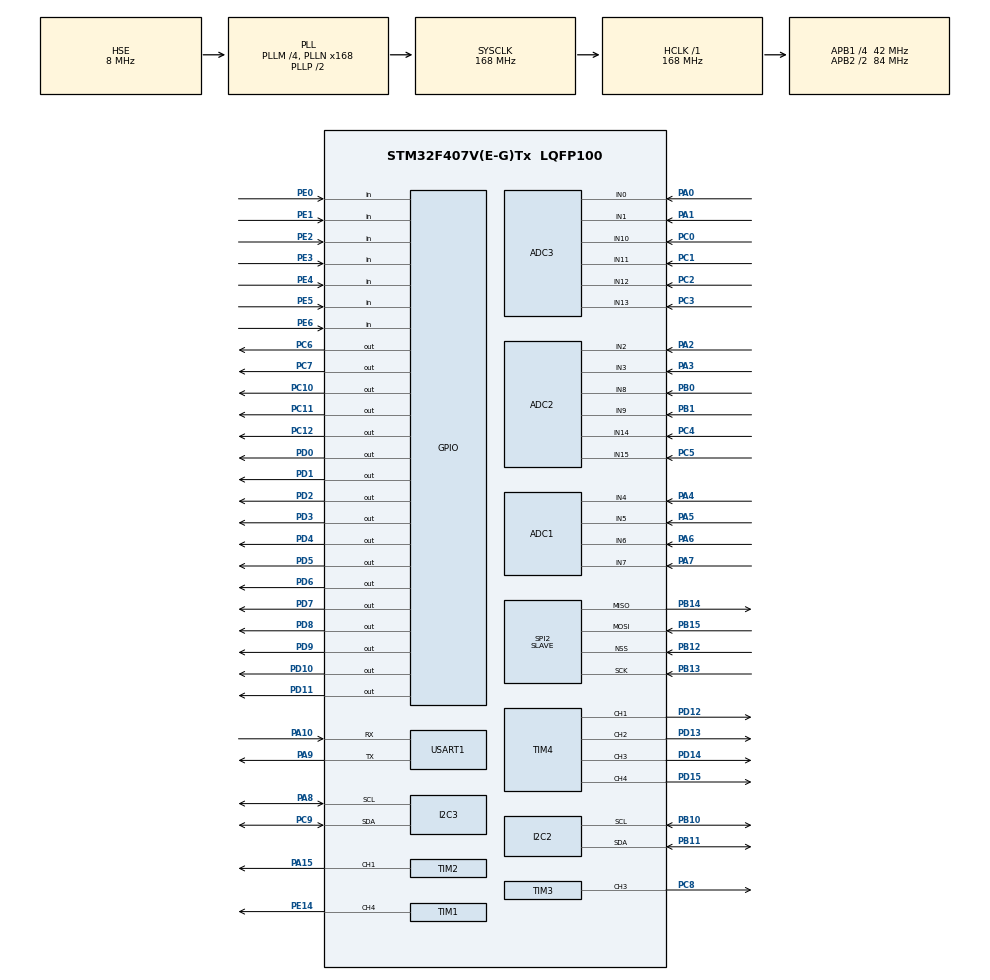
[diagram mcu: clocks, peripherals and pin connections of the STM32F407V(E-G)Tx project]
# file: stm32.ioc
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ADC1.Channel-0\#ChannelRegularConversion=ADC_CHANNEL_TEMPSENSOR
ADC1.ClockPrescaler=ADC_CLOCK_SYNC_PCLK_DIV4
ADC1.NbrOfConversionFlag=1
ADC1.Rank-0\#ChannelRegularConversion=1
ADC1.SamplingTime-0\#ChannelRegularConversion=ADC_SAMPLETIME_3CYCLES
ADC1.master=1
ADC2.Channel-3\#ChannelRegularConversion=ADC_CHANNEL_2
ADC2.ClockPrescaler=ADC_CLOCK_SYNC_PCLK_DIV4
ADC2.NbrOfConversionFlag=1
ADC2.Rank-3\#ChannelRegularConversion=1
ADC2.SamplingTime-3\#ChannelRegularConversion=ADC_SAMPLETIME_3CYCLES
ADC3.Channel-3\#ChannelRegularConversion=ADC_CHANNEL_10
ADC3.ClockPrescaler=ADC_CLOCK_SYNC_PCLK_DIV4
ADC3.NbrOfConversionFlag=1
ADC3.Rank-3\#ChannelRegularConversion=1
ADC3.SamplingTime-3\#ChannelRegularConversion=ADC_SAMPLETIME_3CYCLES
Mcu.Family=STM32F4
Mcu.Name=STM32F407V(E-G)Tx
Mcu.Package=LQFP100
NVIC.PriorityGroup=NVIC_PRIORITYGROUP_4
PA0-WKUP.Signal=ADCx_IN0
PA1.Signal=ADCx_IN1
PA10.Mode=Asynchronous
PA10.Signal=USART1_RX
PA13.Mode=Serial_Wire
PA13.Signal=SYS_JTMS-SWDIO
PA14.Mode=Serial_Wire
PA14.Signal=SYS_JTCK-SWCLK
PA15.Signal=S_TIM2_CH1_ETR
PA2.Signal=ADCx_IN2
PA3.Signal=ADCx_IN3
PA4.Signal=ADCx_IN4
PA5.Signal=ADCx_IN5
PA6.Signal=ADCx_IN6
PA7.Signal=ADCx_IN7
PA8.Mode=I2C
PA8.Signal=I2C3_SCL
PA9.Mode=Asynchronous
PA9.Signal=USART1_TX
PB0.Signal=ADCx_IN8
PB1.Signal=ADCx_IN9
PB10.Mode=I2C
PB10.Signal=I2C2_SCL
PB11.Mode=I2C
PB11.Signal=I2C2_SDA
PB12.Mode=NSS_Signal_Hard_Input
PB12.Signal=SPI2_NSS
PB13.Mode=Full_Duplex_Slave
PB13.Signal=SPI2_SCK
PB14.Mode=Full_Duplex_Slave
PB14.Signal=SPI2_MISO
PB15.Mode=Full_Duplex_Slave
PB15.Signal=SPI2_MOSI
PC0.Signal=ADCx_IN10
PC1.Signal=ADCx_IN11
PC10.Signal=GPIO_Output
PC11.Signal=GPIO_Output
PC12.Signal=GPIO_Output
PC14-OSC32_IN.Mode=LSE-External-Oscillator
PC14-OSC32_IN.Signal=RCC_OSC32_IN
PC15-OSC32_OUT.Mode=LSE-External-Oscillator
PC15-OSC32_OUT.Signal=RCC_OSC32_OUT
PC2.Signal=ADCx_IN12
PC3.Signal=ADCx_IN13
PC4.Signal=ADCx_IN14
PC5.Signal=ADCx_IN15
PC6.Signal=GPIO_Output
PC7.Signal=GPIO_Output
PC8.Signal=S_TIM3_CH3
PC9.Mode=I2C
PC9.Signal=I2C3_SDA
PD0.Signal=GPIO_Output
PD1.Signal=GPIO_Output
PD10.Signal=GPIO_Output
PD11.Signal=GPIO_Output
PD12.Signal=S_TIM4_CH1
PD13.Signal=S_TIM4_CH2
PD14.Signal=S_TIM4_CH3
PD15.Signal=S_TIM4_CH4
PD2.Signal=GPIO_Output
PD3.Signal=GPIO_Output
PD4.Signal=GPIO_Output
PD5.Signal=GPIO_Output
PD6.Signal=GPIO_Output
PD7.Signal=GPIO_Output
PD8.Signal=GPIO_Output
PD9.Signal=GPIO_Output
PE0.Signal=GPIO_Input
PE1.Signal=GPIO_Input
PE14.Signal=S_TIM1_CH4
PE2.Signal=GPIO_Input
PE3.Signal=GPIO_Input
PE4.Signal=GPIO_Input
PE5.Signal=GPIO_Input
PE6.Signal=GPIO_Input
PH0-OSC_IN.Mode=HSE-External-Oscillator
PH0-OSC_IN.Signal=RCC_OSC_IN
PH1-OSC_OUT.Mode=HSE-External-Oscillator
PH1-OSC_OUT.Signal=RCC_OSC_OUT
ProjectManager.HeapSize=0x200
ProjectManager.StackSize=0x400
ProjectManager.TargetToolchain=Makefile
RCC.48MHZClocksFreq_Value=84000000
RCC.AHBFreq_Value=168000000
RCC.APB1CLKDivider=RCC_HCLK_DIV4
RCC.APB1Freq_Value=42000000
RCC.APB1TimFreq_Value=84000000
RCC.APB2CLKDivider=RCC_HCLK_DIV2
RCC.APB2Freq_Value=84000000
RCC.APB2TimFreq_Value=168000000
RCC.CortexFreq_Value=168000000
RCC.HCLKFreq_Value=168000000
RCC.HSE_VALUE=8000000
RCC.HSI_VALUE=16000000
RCC.PLLM=4
RCC.PLLN=168
RCC.PLLSourceVirtual=RCC_PLLSOURCE_HSE
RCC.SYSCLKFreq_VALUE=168000000
RCC.SYSCLKSource=RCC_SYSCLKSOURCE_PLLCLK
RCC.VCOOutputFreq_Value=336000000
SH.ADCx_IN0.0=ADC3_IN0,IN0
SH.ADCx_IN1.0=ADC3_IN1,IN1
SH.ADCx_IN10.0=ADC3_IN10,IN10
SH.ADCx_IN11.0=ADC3_IN11,IN11
SH.ADCx_IN12.0=ADC3_IN12,IN12
SH.ADCx_IN13.0=ADC3_IN13,IN13
SH.ADCx_IN14.0=ADC2_IN14,IN14
SH.ADCx_IN15.0=ADC2_IN15,IN15
SH.ADCx_IN2.0=ADC2_IN2,IN2
SH.ADCx_IN3.0=ADC2_IN3,IN3
SH.ADCx_IN4.0=ADC1_IN4,IN4
SH.ADCx_IN5.0=ADC1_IN5,IN5
SH.ADCx_IN6.0=ADC1_IN6,IN6
SH.ADCx_IN7.0=ADC1_IN7,IN7
SH.ADCx_IN8.0=ADC2_IN8,IN8
SH.ADCx_IN9.0=ADC2_IN9,IN9
SH.S_TIM1_CH4.0=TIM1_CH4,PWM Generation4 CH4
SH.S_TIM2_CH1_ETR.0=TIM2_CH1,PWM Generation1 CH1
SH.S_TIM3_CH3.0=TIM3_CH3,PWM Generation3 CH3
SH.S_TIM4_CH1.0=TIM4_CH1,PWM Generation1 CH1
SH.S_TIM4_CH2.0=TIM4_CH2,PWM Generation2 CH2
SH.S_TIM4_CH3.0=TIM4_CH3,PWM Generation3 CH3
SH.S_TIM4_CH4.0=TIM4_CH4,PWM Generation4 CH4
SPI2.Direction=SPI_DIRECTION_2LINES
SPI2.Mode=SPI_MODE_SLAVE
SPI2.VirtualNSS=VM_NSSHARD
SPI2.VirtualType=VM_SLAVE
TIM1.Channel-PWM\ Generation4\ CH4=TIM_CHANNEL_4
TIM2.Channel-PWM\ Generation1\ CH1=TIM_CHANNEL_1
TIM2.Period=65535
TIM3.Channel-PWM\ Generation3\ CH3=TIM_CHANNEL_3
TIM4.Channel-PWM\ Generation1\ CH1=TIM_CHANNEL_1
TIM4.Channel-PWM\ Generation2\ CH2=TIM_CHANNEL_2
TIM4.Channel-PWM\ Generation3\ CH3=TIM_CHANNEL_3
TIM4.Channel-PWM\ Generation4\ CH4=TIM_CHANNEL_4
USART1.VirtualMode=VM_ASYNC
VP_ADC1_TempSens_Input.Mode=IN-TempSens
VP_ADC1_Vbat_Input.Mode=IN-Vbat
board=custom

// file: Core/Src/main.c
/* USER CODE BEGIN Header */
/**
  ******************************************************************************
  * @file           : main.c
  * @brief          : Main program body
  ******************************************************************************
  * @attention
  *
  * Copyright (c) 2024 STMicroelectronics.
  * All rights reserved.
  *
  * This software is licensed under terms that can be found in the LICENSE file
  * in the root directory of this software component.
  * If no LICENSE file comes with this software, it is provided AS-IS.
  *
  ******************************************************************************
  */
/* USER CODE END Header */
#include "main.h"

ADC_HandleTypeDef hadc1;
ADC_HandleTypeDef hadc2;
ADC_HandleTypeDef hadc3;

I2C_HandleTypeDef hi2c2;
I2C_HandleTypeDef hi2c3;

SPI_HandleTypeDef hspi2;

TIM_HandleTypeDef htim1;
TIM_HandleTypeDef htim2;
TIM_HandleTypeDef htim3;
TIM_HandleTypeDef htim4;

UART_HandleTypeDef huart1;

void SystemClock_Config(void);
static void MX_GPIO_Init(void);
static void MX_ADC1_Init(void);
static void MX_ADC2_Init(void);
static void MX_ADC3_Init(void);
static void MX_I2C2_Init(void);
static void MX_I2C3_Init(void);
static void MX_SPI2_Init(void);
static void MX_TIM1_Init(void);
static void MX_TIM2_Init(void);
static void MX_TIM3_Init(void);
static void MX_TIM4_Init(void);
static void MX_USART1_UART_Init(void);

/* USER CODE BEGIN 0 */

void foo() {
    __asm("nop");
}

void delay() {
    for (int i=0; i<1000000; ++i) {
        foo();
    }
}

/* USER CODE END 0 */

int main(void)
{

  /* MCU Configuration--------------------------------------------------------*/

  /* Reset of all peripherals, Initializes the Flash interface and the Systick. */
  HAL_Init();

  /* Configure the system clock */
  SystemClock_Config();

  /* Initialize all configured peripherals */
  MX_GPIO_Init();
  MX_ADC1_Init();
  MX_ADC2_Init();
  MX_ADC3_Init();
  MX_I2C2_Init();
  MX_I2C3_Init();
  MX_SPI2_Init();
  MX_TIM1_Init();
  MX_TIM2_Init();
  MX_TIM3_Init();
  MX_TIM4_Init();
  MX_USART1_UART_Init();

  /* Infinite loop */
  while (1)
  {
    HAL_GPIO_WritePin(GPIOC, GPIO_PIN_7, GPIO_PIN_RESET);
    delay();
    HAL_GPIO_WritePin(GPIOC, GPIO_PIN_7, GPIO_PIN_SET);
    delay();
  }
}

void SystemClock_Config(void)
{
  RCC_OscInitTypeDef RCC_OscInitStruct = {0};
  RCC_ClkInitTypeDef RCC_ClkInitStruct = {0};

  /** Configure the main internal regulator output voltage
  */
  __HAL_RCC_PWR_CLK_ENABLE();
  __HAL_PWR_VOLTAGESCALING_CONFIG(PWR_REGULATOR_VOLTAGE_SCALE1);

  /** Initializes the RCC Oscillators according to the specified parameters
  * in the RCC_OscInitTypeDef structure.
  */
  RCC_OscInitStruct.OscillatorType = RCC_OSCILLATORTYPE_HSE;
  RCC_OscInitStruct.HSEState = RCC_HSE_ON;
  RCC_OscInitStruct.PLL.PLLState = RCC_PLL_ON;
  RCC_OscInitStruct.PLL.PLLSource = RCC_PLLSOURCE_HSE;
  RCC_OscInitStruct.PLL.PLLM = 4;
  RCC_OscInitStruct.PLL.PLLN = 168;
  RCC_OscInitStruct.PLL.PLLP = RCC_PLLP_DIV2;
  RCC_OscInitStruct.PLL.PLLQ = 4;
  if (HAL_RCC_OscConfig(&RCC_OscInitStruct) != HAL_OK)
  {
    Error_Handler();
  }

  /** Initializes the CPU, AHB and APB buses clocks
  */
  RCC_ClkInitStruct.ClockType = RCC_CLOCKTYPE_HCLK|RCC_CLOCKTYPE_SYSCLK
                              |RCC_CLOCKTYPE_PCLK1|RCC_CLOCKTYPE_PCLK2;
  RCC_ClkInitStruct.SYSCLKSource = RCC_SYSCLKSOURCE_PLLCLK;
  RCC_ClkInitStruct.AHBCLKDivider = RCC_SYSCLK_DIV1;
  RCC_ClkInitStruct.APB1CLKDivider = RCC_HCLK_DIV4;
  RCC_ClkInitStruct.APB2CLKDivider = RCC_HCLK_DIV2;

  if (HAL_RCC_ClockConfig(&RCC_ClkInitStruct, FLASH_LATENCY_5) != HAL_OK)
  {
    Error_Handler();
  }
}

static void MX_ADC1_Init(void)
{

  ADC_ChannelConfTypeDef sConfig = {0};

  /** Configure the global features of the ADC (Clock, Resolution, Data Alignment and number of conversion)
  */
  hadc1.Instance = ADC1;
  hadc1.Init.ClockPrescaler = ADC_CLOCK_SYNC_PCLK_DIV4;
  hadc1.Init.Resolution = ADC_RESOLUTION_12B;
  hadc1.Init.ScanConvMode = DISABLE;
  hadc1.Init.ContinuousConvMode = DISABLE;
  hadc1.Init.DiscontinuousConvMode = DISABLE;
  hadc1.Init.ExternalTrigConvEdge = ADC_EXTERNALTRIGCONVEDGE_NONE;
  hadc1.Init.ExternalTrigConv = ADC_SOFTWARE_START;
  hadc1.Init.DataAlign = ADC_DATAALIGN_RIGHT;
  hadc1.Init.NbrOfConversion = 1;
  hadc1.Init.DMAContinuousRequests = DISABLE;
  hadc1.Init.EOCSelection = ADC_EOC_SINGLE_CONV;
  if (HAL_ADC_Init(&hadc1) != HAL_OK)
  {
    Error_Handler();
  }

  /** Configure for the selected ADC regular channel its corresponding rank in the sequencer and its sample time.
  */
  sConfig.Channel = ADC_CHANNEL_TEMPSENSOR;
  sConfig.Rank = 1;
  sConfig.SamplingTime = ADC_SAMPLETIME_3CYCLES;
  if (HAL_ADC_ConfigChannel(&hadc1, &sConfig) != HAL_OK)
  {
    Error_Handler();
  }

}

static void MX_ADC2_Init(void)
{

  ADC_ChannelConfTypeDef sConfig = {0};

  /** Configure the global features of the ADC (Clock, Resolution, Data Alignment and number of conversion)
  */
  hadc2.Instance = ADC2;
  hadc2.Init.ClockPrescaler = ADC_CLOCK_SYNC_PCLK_DIV4;
  hadc2.Init.Resolution = ADC_RESOLUTION_12B;
  hadc2.Init.ScanConvMode = DISABLE;
  hadc2.Init.ContinuousConvMode = DISABLE;
  hadc2.Init.DiscontinuousConvMode = DISABLE;
  hadc2.Init.ExternalTrigConvEdge = ADC_EXTERNALTRIGCONVEDGE_NONE;
  hadc2.Init.ExternalTrigConv = ADC_SOFTWARE_START;
  hadc2.Init.DataAlign = ADC_DATAALIGN_RIGHT;
  hadc2.Init.NbrOfConversion = 1;
  hadc2.Init.DMAContinuousRequests = DISABLE;
  hadc2.Init.EOCSelection = ADC_EOC_SINGLE_CONV;
  if (HAL_ADC_Init(&hadc2) != HAL_OK)
  {
    Error_Handler();
  }

  /** Configure for the selected ADC regular channel its corresponding rank in the sequencer and its sample time.
  */
  sConfig.Channel = ADC_CHANNEL_2;
  sConfig.Rank = 1;
  sConfig.SamplingTime = ADC_SAMPLETIME_3CYCLES;
  if (HAL_ADC_ConfigChannel(&hadc2, &sConfig) != HAL_OK)
  {
    Error_Handler();
  }

}

static void MX_ADC3_Init(void)
{

  ADC_ChannelConfTypeDef sConfig = {0};

  /** Configure the global features of the ADC (Clock, Resolution, Data Alignment and number of conversion)
  */
  hadc3.Instance = ADC3;
  hadc3.Init.ClockPrescaler = ADC_CLOCK_SYNC_PCLK_DIV4;
  hadc3.Init.Resolution = ADC_RESOLUTION_12B;
  hadc3.Init.ScanConvMode = DISABLE;
  hadc3.Init.ContinuousConvMode = DISABLE;
  hadc3.Init.DiscontinuousConvMode = DISABLE;
  hadc3.Init.ExternalTrigConvEdge = ADC_EXTERNALTRIGCONVEDGE_NONE;
  hadc3.Init.ExternalTrigConv = ADC_SOFTWARE_START;
  hadc3.Init.DataAlign = ADC_DATAALIGN_RIGHT;
  hadc3.Init.NbrOfConversion = 1;
  hadc3.Init.DMAContinuousRequests = DISABLE;
  hadc3.Init.EOCSelection = ADC_EOC_SINGLE_CONV;
  if (HAL_ADC_Init(&hadc3) != HAL_OK)
  {
    Error_Handler();
  }

  /** Configure for the selected ADC regular channel its corresponding rank in the sequencer and its sample time.
  */
  sConfig.Channel = ADC_CHANNEL_10;
  sConfig.Rank = 1;
  sConfig.SamplingTime = ADC_SAMPLETIME_3CYCLES;
  if (HAL_ADC_ConfigChannel(&hadc3, &sConfig) != HAL_OK)
  {
    Error_Handler();
  }

}

static void MX_I2C2_Init(void)
{

  hi2c2.Instance = I2C2;
  hi2c2.Init.ClockSpeed = 100000;
  hi2c2.Init.DutyCycle = I2C_DUTYCYCLE_2;
  hi2c2.Init.OwnAddress1 = 0;
  hi2c2.Init.AddressingMode = I2C_ADDRESSINGMODE_7BIT;
  hi2c2.Init.DualAddressMode = I2C_DUALADDRESS_DISABLE;
  hi2c2.Init.OwnAddress2 = 0;
  hi2c2.Init.GeneralCallMode = I2C_GENERALCALL_DISABLE;
  hi2c2.Init.NoStretchMode = I2C_NOSTRETCH_DISABLE;
  if (HAL_I2C_Init(&hi2c2) != HAL_OK)
  {
    Error_Handler();
  }

}

static void MX_I2C3_Init(void)
{

  hi2c3.Instance = I2C3;
  hi2c3.Init.ClockSpeed = 100000;
  hi2c3.Init.DutyCycle = I2C_DUTYCYCLE_2;
  hi2c3.Init.OwnAddress1 = 0;
  hi2c3.Init.AddressingMode = I2C_ADDRESSINGMODE_7BIT;
  hi2c3.Init.DualAddressMode = I2C_DUALADDRESS_DISABLE;
  hi2c3.Init.OwnAddress2 = 0;
  hi2c3.Init.GeneralCallMode = I2C_GENERALCALL_DISABLE;
  hi2c3.Init.NoStretchMode = I2C_NOSTRETCH_DISABLE;
  if (HAL_I2C_Init(&hi2c3) != HAL_OK)
  {
    Error_Handler();
  }

}

static void MX_SPI2_Init(void)
{

  /* SPI2 parameter configuration*/
  hspi2.Instance = SPI2;
  hspi2.Init.Mode = SPI_MODE_SLAVE;
  hspi2.Init.Direction = SPI_DIRECTION_2LINES;
  hspi2.Init.DataSize = SPI_DATASIZE_8BIT;
  hspi2.Init.CLKPolarity = SPI_POLARITY_LOW;
  hspi2.Init.CLKPhase = SPI_PHASE_1EDGE;
  hspi2.Init.NSS = SPI_NSS_HARD_INPUT;
  hspi2.Init.FirstBit = SPI_FIRSTBIT_MSB;
  hspi2.Init.TIMode = SPI_TIMODE_DISABLE;
  hspi2.Init.CRCCalculation = SPI_CRCCALCULATION_DISABLE;
  hspi2.Init.CRCPolynomial = 10;
  if (HAL_SPI_Init(&hspi2) != HAL_OK)
  {
    Error_Handler();
  }

}

static void MX_TIM1_Init(void)
{

  TIM_MasterConfigTypeDef sMasterConfig = {0};
  TIM_OC_InitTypeDef sConfigOC = {0};
  TIM_BreakDeadTimeConfigTypeDef sBreakDeadTimeConfig = {0};

  htim1.Instance = TIM1;
  htim1.Init.Prescaler = 0;
  htim1.Init.CounterMode = TIM_COUNTERMODE_UP;
  htim1.Init.Period = 65535;
  htim1.Init.ClockDivision = TIM_CLOCKDIVISION_DIV1;
  htim1.Init.RepetitionCounter = 0;
  htim1.Init.AutoReloadPreload = TIM_AUTORELOAD_PRELOAD_DISABLE;
  if (HAL_TIM_PWM_Init(&htim1) != HAL_OK)
  {
    Error_Handler();
  }
  sMasterConfig.MasterOutputTrigger = TIM_TRGO_RESET;
  sMasterConfig.MasterSlaveMode = TIM_MASTERSLAVEMODE_DISABLE;
  if (HAL_TIMEx_MasterConfigSynchronization(&htim1, &sMasterConfig) != HAL_OK)
  {
    Error_Handler();
  }
  sConfigOC.OCMode = TIM_OCMODE_PWM1;
  sConfigOC.Pulse = 0;
  sConfigOC.OCPolarity = TIM_OCPOLARITY_HIGH;
  sConfigOC.OCFastMode = TIM_OCFAST_DISABLE;
  sConfigOC.OCIdleState = TIM_OCIDLESTATE_RESET;
  sConfigOC.OCNIdleState = TIM_OCNIDLESTATE_RESET;
  if (HAL_TIM_PWM_ConfigChannel(&htim1, &sConfigOC, TIM_CHANNEL_4) != HAL_OK)
  {
    Error_Handler();
  }
  sBreakDeadTimeConfig.OffStateRunMode = TIM_OSSR_DISABLE;
  sBreakDeadTimeConfig.OffStateIDLEMode = TIM_OSSI_DISABLE;
  sBreakDeadTimeConfig.LockLevel = TIM_LOCKLEVEL_OFF;
  sBreakDeadTimeConfig.DeadTime = 0;
  sBreakDeadTimeConfig.BreakState = TIM_BREAK_DISABLE;
  sBreakDeadTimeConfig.BreakPolarity = TIM_BREAKPOLARITY_HIGH;
  sBreakDeadTimeConfig.AutomaticOutput = TIM_AUTOMATICOUTPUT_DISABLE;
  if (HAL_TIMEx_ConfigBreakDeadTime(&htim1, &sBreakDeadTimeConfig) != HAL_OK)
  {
    Error_Handler();
  }
  HAL_TIM_MspPostInit(&htim1);

}

static void MX_TIM2_Init(void)
{

  TIM_MasterConfigTypeDef sMasterConfig = {0};
  TIM_OC_InitTypeDef sConfigOC = {0};

  htim2.Instance = TIM2;
  htim2.Init.Prescaler = 0;
  htim2.Init.CounterMode = TIM_COUNTERMODE_UP;
  htim2.Init.Period = 65535;
  htim2.Init.ClockDivision = TIM_CLOCKDIVISION_DIV1;
  htim2.Init.AutoReloadPreload = TIM_AUTORELOAD_PRELOAD_DISABLE;
  if (HAL_TIM_PWM_Init(&htim2) != HAL_OK)
  {
    Error_Handler();
  }
  sMasterConfig.MasterOutputTrigger = TIM_TRGO_RESET;
  sMasterConfig.MasterSlaveMode = TIM_MASTERSLAVEMODE_DISABLE;
  if (HAL_TIMEx_MasterConfigSynchronization(&htim2, &sMasterConfig) != HAL_OK)
  {
    Error_Handler();
  }
  sConfigOC.OCMode = TIM_OCMODE_PWM1;
  sConfigOC.Pulse = 0;
  sConfigOC.OCPolarity = TIM_OCPOLARITY_HIGH;
  sConfigOC.OCFastMode = TIM_OCFAST_DISABLE;
  if (HAL_TIM_PWM_ConfigChannel(&htim2, &sConfigOC, TIM_CHANNEL_1) != HAL_OK)
  {
    Error_Handler();
  }
  HAL_TIM_MspPostInit(&htim2);

}

static void MX_TIM3_Init(void)
{

  TIM_MasterConfigTypeDef sMasterConfig = {0};
  TIM_OC_InitTypeDef sConfigOC = {0};

  htim3.Instance = TIM3;
  htim3.Init.Prescaler = 0;
  htim3.Init.CounterMode = TIM_COUNTERMODE_UP;
  htim3.Init.Period = 65535;
  htim3.Init.ClockDivision = TIM_CLOCKDIVISION_DIV1;
  htim3.Init.AutoReloadPreload = TIM_AUTORELOAD_PRELOAD_DISABLE;
  if (HAL_TIM_PWM_Init(&htim3) != HAL_OK)
  {
    Error_Handler();
  }
  sMasterConfig.MasterOutputTrigger = TIM_TRGO_RESET;
  sMasterConfig.MasterSlaveMode = TIM_MASTERSLAVEMODE_DISABLE;
  if (HAL_TIMEx_MasterConfigSynchronization(&htim3, &sMasterConfig) != HAL_OK)
  {
    Error_Handler();
  }
  sConfigOC.OCMode = TIM_OCMODE_PWM1;
  sConfigOC.Pulse = 0;
  sConfigOC.OCPolarity = TIM_OCPOLARITY_HIGH;
  sConfigOC.OCFastMode = TIM_OCFAST_DISABLE;
  if (HAL_TIM_PWM_ConfigChannel(&htim3, &sConfigOC, TIM_CHANNEL_3) != HAL_OK)
  {
    Error_Handler();
  }
  HAL_TIM_MspPostInit(&htim3);

}

static void MX_TIM4_Init(void)
{

  TIM_MasterConfigTypeDef sMasterConfig = {0};
  TIM_OC_InitTypeDef sConfigOC = {0};

  htim4.Instance = TIM4;
  htim4.Init.Prescaler = 0;
  htim4.Init.CounterMode = TIM_COUNTERMODE_UP;
  htim4.Init.Period = 65535;
  htim4.Init.ClockDivision = TIM_CLOCKDIVISION_DIV1;
  htim4.Init.AutoReloadPreload = TIM_AUTORELOAD_PRELOAD_DISABLE;
  if (HAL_TIM_PWM_Init(&htim4) != HAL_OK)
  {
    Error_Handler();
  }
  sMasterConfig.MasterOutputTrigger = TIM_TRGO_RESET;
  sMasterConfig.MasterSlaveMode = TIM_MASTERSLAVEMODE_DISABLE;
  if (HAL_TIMEx_MasterConfigSynchronization(&htim4, &sMasterConfig) != HAL_OK)
  {
    Error_Handler();
  }
  sConfigOC.OCMode = TIM_OCMODE_PWM1;
  sConfigOC.Pulse = 0;
  sConfigOC.OCPolarity = TIM_OCPOLARITY_HIGH;
  sConfigOC.OCFastMode = TIM_OCFAST_DISABLE;
  if (HAL_TIM_PWM_ConfigChannel(&htim4, &sConfigOC, TIM_CHANNEL_1) != HAL_OK)
  {
    Error_Handler();
  }
  if (HAL_TIM_PWM_ConfigChannel(&htim4, &sConfigOC, TIM_CHANNEL_2) != HAL_OK)
  {
    Error_Handler();
  }
  if (HAL_TIM_PWM_ConfigChannel(&htim4, &sConfigOC, TIM_CHANNEL_3) != HAL_OK)
  {
    Error_Handler();
  }
  if (HAL_TIM_PWM_ConfigChannel(&htim4, &sConfigOC, TIM_CHANNEL_4) != HAL_OK)
  {
    Error_Handler();
  }
  HAL_TIM_MspPostInit(&htim4);

}

static void MX_USART1_UART_Init(void)
{

  huart1.Instance = USART1;
  huart1.Init.BaudRate = 115200;
  huart1.Init.WordLength = UART_WORDLENGTH_8B;
  huart1.Init.StopBits = UART_STOPBITS_1;
  huart1.Init.Parity = UART_PARITY_NONE;
  huart1.Init.Mode = UART_MODE_TX_RX;
  huart1.Init.HwFlowCtl = UART_HWCONTROL_NONE;
  huart1.Init.OverSampling = UART_OVERSAMPLING_16;
  if (HAL_UART_Init(&huart1) != HAL_OK)
  {
    Error_Handler();
  }

}

static void MX_GPIO_Init(void)
{
  GPIO_InitTypeDef GPIO_InitStruct = {0};

  /* GPIO Ports Clock Enable */
  __HAL_RCC_GPIOE_CLK_ENABLE();
  __HAL_RCC_GPIOC_CLK_ENABLE();
  __HAL_RCC_GPIOH_CLK_ENABLE();
  __HAL_RCC_GPIOA_CLK_ENABLE();
  __HAL_RCC_GPIOB_CLK_ENABLE();
  __HAL_RCC_GPIOD_CLK_ENABLE();

  /*Configure GPIO pin Output Level */
  HAL_GPIO_WritePin(GPIOD, GPIO_PIN_8|GPIO_PIN_9|GPIO_PIN_10|GPIO_PIN_11
                          |GPIO_PIN_0|GPIO_PIN_1|GPIO_PIN_2|GPIO_PIN_3
                          |GPIO_PIN_4|GPIO_PIN_5|GPIO_PIN_6|GPIO_PIN_7, GPIO_PIN_RESET);

  /*Configure GPIO pin Output Level */
  HAL_GPIO_WritePin(GPIOC, GPIO_PIN_6|GPIO_PIN_7|GPIO_PIN_10|GPIO_PIN_11
                          |GPIO_PIN_12, GPIO_PIN_RESET);

  /*Configure GPIO pins : PE2 PE3 PE4 PE5
                           PE6 PE0 PE1 */
  GPIO_InitStruct.Pin = GPIO_PIN_2|GPIO_PIN_3|GPIO_PIN_4|GPIO_PIN_5
                          |GPIO_PIN_6|GPIO_PIN_0|GPIO_PIN_1;
  GPIO_InitStruct.Mode = GPIO_MODE_INPUT;
  GPIO_InitStruct.Pull = GPIO_NOPULL;
  HAL_GPIO_Init(GPIOE, &GPIO_InitStruct);

  /*Configure GPIO pins : PD8 PD9 PD10 PD11
                           PD0 PD1 PD2 PD3
                           PD4 PD5 PD6 PD7 */
  GPIO_InitStruct.Pin = GPIO_PIN_8|GPIO_PIN_9|GPIO_PIN_10|GPIO_PIN_11
                          |GPIO_PIN_0|GPIO_PIN_1|GPIO_PIN_2|GPIO_PIN_3
                          |GPIO_PIN_4|GPIO_PIN_5|GPIO_PIN_6|GPIO_PIN_7;
  GPIO_InitStruct.Mode = GPIO_MODE_OUTPUT_PP;
  GPIO_InitStruct.Pull = GPIO_NOPULL;
  GPIO_InitStruct.Speed = GPIO_SPEED_FREQ_LOW;
  HAL_GPIO_Init(GPIOD, &GPIO_InitStruct);

  /*Configure GPIO pins : PC6 PC7 PC10 PC11
                           PC12 */
  GPIO_InitStruct.Pin = GPIO_PIN_6|GPIO_PIN_7|GPIO_PIN_10|GPIO_PIN_11
                          |GPIO_PIN_12;
  GPIO_InitStruct.Mode = GPIO_MODE_OUTPUT_PP;
  GPIO_InitStruct.Pull = GPIO_NOPULL;
  GPIO_InitStruct.Speed = GPIO_SPEED_FREQ_LOW;
  HAL_GPIO_Init(GPIOC, &GPIO_InitStruct);

}

void Error_Handler(void)
{
  __disable_irq();
  while (1)
  {
  }
}
